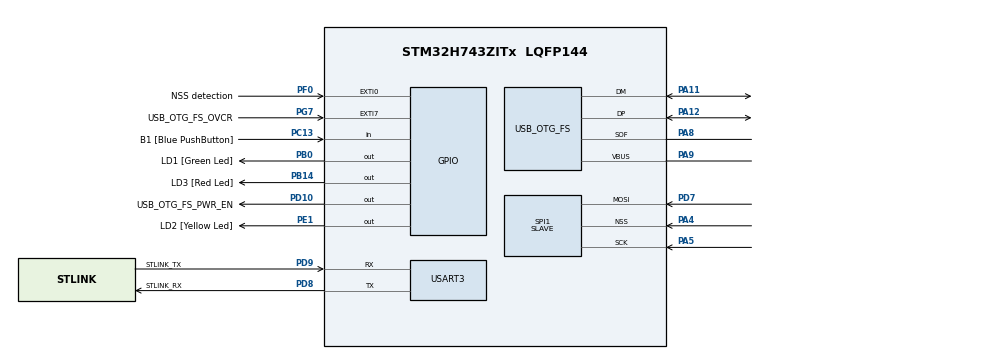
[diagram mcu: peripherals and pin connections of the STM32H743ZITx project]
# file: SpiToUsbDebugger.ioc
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Mcu.Family=STM32H7
PD7.Mode=RX_Only_Simplex_Unidirect_Slave
USB_DEVICE.CLASS_NAME_FS=CDC
RCC.CortexFreq_Value=96000000
SPI1.VirtualType=VM_SLAVE
PH0-OSC_IN\ (PH0).Signal=RCC_OSC_IN
PB14.GPIO_Label=LD3 [Red Led]
PC15-OSC32_OUT\ (OSC32_OUT).Mode=LSE-External-Oscillator
RCC.PLLFRACN=0
PA11.Mode=Device_Only
PB0.GPIO_Label=LD1 [Green Led]
USB_DEVICE.VirtualMode-CDC_FS=Cdc
NVIC.TIM1_UP_IRQn=true\:0\:0\:false\:false\:true\:true\:true
PC13.GPIO_Label=B1 [Blue PushButton]
PB13.Signal=ETH_TXD1
PG13.Signal=ETH_TXD0
PD9.Mode=Asynchronous
PG11.Signal=ETH_TX_EN
RCC.SYSCLKSource=RCC_SYSCLKSOURCE_PLLCLK
ProjectManager.StackSize=0x500
Dma.SPI1_RX.0.SyncRequestNumber=1
USART3.VirtualMode-Asynchronous=VM_ASYNC
PA12.Signal=USB_OTG_FS_DP
TIM1.Prescaler=95
Dma.SPI1_RX.0.Direction=DMA_PERIPH_TO_MEMORY
PA4.Mode=NSS_Signal_Hard_Input
SPI1.Direction=SPI_DIRECTION_2LINES_RXONLY
RCC.HCLKFreq_Value=96000000
PD8.Signal=USART3_TX
PE1.Signal=GPIO_Output
RCC.HSE_VALUE=8000000
RCC.DIVM1=1
Dma.SPI1_RX.0.RequestNumber=1
Dma.SPI1_RX.0.PeriphInc=DMA_PINC_DISABLE
Dma.SPI1_RX.0.SyncEnable=DISABLE
SPI1.DataSize=SPI_DATASIZE_8BIT
PA8.Signal=USB_OTG_FS_SOF
SPI1.VirtualNSS=VM_NSSHARD
USB_OTG_FS.dma_enable=DISABLE
Dma.SPI1_RX.0.Polarity=HAL_DMAMUX_REQ_GEN_RISING
VP_TIM1_VS_ClockSourceINT.Mode=Internal
RCC.APB3Freq_Value=96000000
Mcu.Package=LQFP144
NVIC.OTG_FS_IRQn=true\:0\:0\:false\:false\:true\:false\:true
USB_OTG_FS.VirtualMode=Device_Only
PC14-OSC32_IN\ (OSC32_IN).Mode=LSE-External-Oscillator
RCC.APB4Freq_Value=96000000
NVIC.DMA1_Stream0_IRQn=true\:0\:0\:false\:false\:true\:false\:true
PF0.Signal=GPXTI0
PC5.Signal=ETH_RXD1
TIM1.Period=333
Dma.Request0=SPI1_RX
PH0-OSC_IN\ (PH0).Mode=HSE-External-Clock-Source
PA5.Mode=RX_Only_Simplex_Unidirect_Slave
RCC.DIVQ1=4
PG7.Signal=GPXTI7
PD9.GPIO_Label=STLINK_TX
USB_DEVICE.VirtualModeFS=Cdc_FS
PC13.Signal=GPIO_Input
PC4.Signal=ETH_RXD0
PD7.Signal=SPI1_MOSI
RCC.D2PPRE1=RCC_APB1_DIV2
PD9.Signal=USART3_RX
Dma.SPI1_RX.0.Mode=DMA_CIRCULAR
PH1-OSC_OUT\ (PH1).Signal=RCC_OSC_OUT
PD8.GPIO_Label=STLINK_RX
PD10.Signal=GPIO_Output
Dma.SPI1_RX.0.FIFOMode=DMA_FIFOMODE_DISABLE
PA9.Mode=Activate_VBUS
ProjectManager.TargetToolchain=STM32CubeIDE
PC15-OSC32_OUT\ (OSC32_OUT).Signal=RCC_OSC32_OUT
VP_USB_DEVICE_VS_USB_DEVICE_CDC_FS.Mode=CDC_FS
PA9.Signal=USB_OTG_FS_VBUS
RCC.DIVN1=24
RCC.USBFreq_Value=48000000
Dma.SPI1_RX.0.EventEnable=DISABLE
PD10.GPIO_Label=USB_OTG_FS_PWR_EN
PD8.Mode=Asynchronous
PA1.Signal=ETH_REF_CLK
PB14.Signal=GPIO_Output
PA5.Signal=SPI1_SCK
board=NUCLEO-H743ZI2
PE1.GPIO_Label=LD2 [Yellow Led]
NVIC.SPI1_IRQn=true\:0\:0\:false\:false\:true\:true\:true
RCC.APB2Freq_Value=96000000
SPI1.Mode=SPI_MODE_SLAVE
PG7.GPIO_Label=USB_OTG_FS_OVCR
Dma.SPI1_RX.0.Instance=DMA1_Stream0
RCC.ADCFreq_Value=16125000
Dma.SPI1_RX.0.PeriphDataAlignment=DMA_PDATAALIGN_BYTE
Dma.SPI1_RX.0.SyncSignalID=NONE
Dma.SPI1_RX.0.MemDataAlignment=DMA_MDATAALIGN_BYTE
Mcu.Name=STM32H743ZITx
Dma.SPI1_RX.0.MemInc=DMA_MINC_ENABLE
PA2.Signal=ETH_MDIO
NVIC.EXTI0_IRQn=true\:0\:0\:false\:false\:true\:true\:true
PA4.Signal=SPI1_NSS
RCC.SYSCLKFreq_VALUE=96000000
Dma.SPI1_RX.0.SignalID=NONE
PA12.Mode=Device_Only
PC14-OSC32_IN\ (OSC32_IN).Signal=RCC_OSC32_IN
PA11.Signal=USB_OTG_FS_DM
ProjectManager.HeapSize=0x200
Dma.SPI1_RX.0.Priority=DMA_PRIORITY_LOW
Dma.SPI1_RX.0.SyncPolarity=HAL_DMAMUX_SYNC_NO_EVENT
NVIC.PriorityGroup=NVIC_PRIORITYGROUP_4
PF0.GPIO_Label=NSS detection
PA8.Mode=Activate_SOF_FS
RCC.APB1Freq_Value=48000000
PB0.Signal=GPIO_Output
PC1.Signal=ETH_MDC
PA7.Signal=ETH_CRS_DV

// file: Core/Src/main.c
/* USER CODE BEGIN Header */
/**
  ******************************************************************************
  * @file           : main.c
  * @brief          : Main program body
  ******************************************************************************
  * @attention
  *
  * <h2><center>&copy; Copyright (c) 2024 STMicroelectronics.
  * All rights reserved.</center></h2>
  *
  * This software component is licensed by ST under Ultimate Liberty license
  * SLA0044, the "License"; You may not use this file except in compliance with
  * the License. You may obtain a copy of the License at:
  *                             www.st.com/SLA0044
  *
  ******************************************************************************
  */
/* USER CODE END Header */
#include "main.h"
#include "usb_device.h"

/* USER CODE BEGIN Includes */
#include "usbd_cdc_if.h"
extern uint8_t FlushFlag;
/* USER CODE END Includes */

/* USER CODE BEGIN PM */
uint32_t gData_from_spi;
/* USER CODE END PM */

SPI_HandleTypeDef hspi1;
DMA_HandleTypeDef hdma_spi1_rx;

TIM_HandleTypeDef htim1;

UART_HandleTypeDef huart3;

/* USER CODE BEGIN PV */
int g_enable_usb_push;
/* USER CODE END PV */

void SystemClock_Config(void);
static void MX_GPIO_Init(void);
static void MX_DMA_Init(void);
static void MX_SPI1_Init(void);
static void MX_USART3_UART_Init(void);
static void MX_TIM1_Init(void);

/* USER CODE BEGIN 0 */

void HAL_GPIO_EXTI_Callback(uint16_t GPIO_Pin)
{
	HAL_SPI_Receive_DMA(&hspi1, (uint8_t*)&gData_from_spi, 4);
	HAL_NVIC_DisableIRQ(EXTI0_IRQn);

}

void HAL_SPI_RxCpltCallback(SPI_HandleTypeDef *hspi)
{
	CDC_TransmitWithFifo_FS((uint8_t*)&gData_from_spi, sizeof(gData_from_spi));
	 //HAL_SPI_Receive_IT(&hspi1, (uint8_t*)&gData_from_spi, 4);
	//static int state = 0;
	// we have new data from SPI
//	switch (state)
//	{
//	case 0:
//		gDataAssembly = 0;
//		if(gData_from_spi == 0)
//			state =1;
//		break;
//	case 1:
//		gDataAssembly |= (uint32_t)gData_from_spi;
//		state = 2;
//		break;
//	case 2:
//		gDataAssembly |= (uint32_t)gData_from_spi<<8;
//		state = 3;
//		break;
//	case 3:
//		gDataAssembly |= (uint32_t)gData_from_spi<<16;
//		state = 4;
//		break;
//	case 4:
//		gDataAssembly |= (uint32_t)gData_from_spi<<24;
//		state = 5;
//		break;
//	case 5:
//		if(gData_from_spi == 0xff)
//			CDC_TransmitWithFifo_FS((uint8_t*)&gDataAssembly, sizeof(gDataAssembly));
//		state = 0;
//		break;
//	}

}
/* USER CODE END 0 */

int main(void)
{

  /* MCU Configuration--------------------------------------------------------*/

  /* Reset of all peripherals, Initializes the Flash interface and the Systick. */
  HAL_Init();

  /* Configure the system clock */
  SystemClock_Config();

  /* Initialize all configured peripherals */
  MX_GPIO_Init();
  MX_DMA_Init();
  MX_SPI1_Init();
  MX_USART3_UART_Init();
  MX_USB_DEVICE_Init();
  MX_TIM1_Init();
  /* USER CODE BEGIN 2 */
  //HAL_TIM_Base_Start_IT(&htim1);
  HAL_NVIC_SetPriority(EXTI0_IRQn, 10, 10);
  HAL_NVIC_EnableIRQ(EXTI0_IRQn);

 // CLEAR_BIT(hspi1.Instance->CR1 , SPI_CR1_SPE);
  /* USER CODE END 2 */

  /* Infinite loop */
  while (1)
  {
	  if(FlushFlag)
	  {
		  uint8_t retval = CDC_TxFifoFlush();
		  if(retval == 0)
		  {
			  FlushFlag = 0;
		  }
	  }
  }
}

void SystemClock_Config(void)
{
  RCC_OscInitTypeDef RCC_OscInitStruct = {0};
  RCC_ClkInitTypeDef RCC_ClkInitStruct = {0};

  /** Supply configuration update enable
  */
  HAL_PWREx_ConfigSupply(PWR_LDO_SUPPLY);
  /** Configure the main internal regulator output voltage
  */
  __HAL_PWR_VOLTAGESCALING_CONFIG(PWR_REGULATOR_VOLTAGE_SCALE3);

  while(!__HAL_PWR_GET_FLAG(PWR_FLAG_VOSRDY)) {}
  /** Initializes the RCC Oscillators according to the specified parameters
  * in the RCC_OscInitTypeDef structure.
  */
  RCC_OscInitStruct.OscillatorType = RCC_OSCILLATORTYPE_HSE;
  RCC_OscInitStruct.HSEState = RCC_HSE_BYPASS;
  RCC_OscInitStruct.PLL.PLLState = RCC_PLL_ON;
  RCC_OscInitStruct.PLL.PLLSource = RCC_PLLSOURCE_HSE;
  RCC_OscInitStruct.PLL.PLLM = 1;
  RCC_OscInitStruct.PLL.PLLN = 24;
  RCC_OscInitStruct.PLL.PLLP = 2;
  RCC_OscInitStruct.PLL.PLLQ = 4;
  RCC_OscInitStruct.PLL.PLLR = 2;
  RCC_OscInitStruct.PLL.PLLRGE = RCC_PLL1VCIRANGE_3;
  RCC_OscInitStruct.PLL.PLLVCOSEL = RCC_PLL1VCOWIDE;
  RCC_OscInitStruct.PLL.PLLFRACN = 0;
  if (HAL_RCC_OscConfig(&RCC_OscInitStruct) != HAL_OK)
  {
    Error_Handler();
  }
  /** Initializes the CPU, AHB and APB buses clocks
  */
  RCC_ClkInitStruct.ClockType = RCC_CLOCKTYPE_HCLK|RCC_CLOCKTYPE_SYSCLK
                              |RCC_CLOCKTYPE_PCLK1|RCC_CLOCKTYPE_PCLK2
                              |RCC_CLOCKTYPE_D3PCLK1|RCC_CLOCKTYPE_D1PCLK1;
  RCC_ClkInitStruct.SYSCLKSource = RCC_SYSCLKSOURCE_PLLCLK;
  RCC_ClkInitStruct.SYSCLKDivider = RCC_SYSCLK_DIV1;
  RCC_ClkInitStruct.AHBCLKDivider = RCC_HCLK_DIV1;
  RCC_ClkInitStruct.APB3CLKDivider = RCC_APB3_DIV1;
  RCC_ClkInitStruct.APB1CLKDivider = RCC_APB1_DIV2;
  RCC_ClkInitStruct.APB2CLKDivider = RCC_APB2_DIV1;
  RCC_ClkInitStruct.APB4CLKDivider = RCC_APB4_DIV1;

  if (HAL_RCC_ClockConfig(&RCC_ClkInitStruct, FLASH_LATENCY_2) != HAL_OK)
  {
    Error_Handler();
  }
}

static void MX_SPI1_Init(void)
{

  /* SPI1 parameter configuration*/
  hspi1.Instance = SPI1;
  hspi1.Init.Mode = SPI_MODE_SLAVE;
  hspi1.Init.Direction = SPI_DIRECTION_2LINES_RXONLY;
  hspi1.Init.DataSize = SPI_DATASIZE_8BIT;
  hspi1.Init.CLKPolarity = SPI_POLARITY_LOW;
  hspi1.Init.CLKPhase = SPI_PHASE_1EDGE;
  hspi1.Init.NSS = SPI_NSS_HARD_INPUT;
  hspi1.Init.FirstBit = SPI_FIRSTBIT_MSB;
  hspi1.Init.TIMode = SPI_TIMODE_DISABLE;
  hspi1.Init.CRCCalculation = SPI_CRCCALCULATION_DISABLE;
  hspi1.Init.CRCPolynomial = 0x0;
  hspi1.Init.NSSPMode = SPI_NSS_PULSE_DISABLE;
  hspi1.Init.NSSPolarity = SPI_NSS_POLARITY_LOW;
  hspi1.Init.FifoThreshold = SPI_FIFO_THRESHOLD_01DATA;
  hspi1.Init.TxCRCInitializationPattern = SPI_CRC_INITIALIZATION_ALL_ZERO_PATTERN;
  hspi1.Init.RxCRCInitializationPattern = SPI_CRC_INITIALIZATION_ALL_ZERO_PATTERN;
  hspi1.Init.MasterSSIdleness = SPI_MASTER_SS_IDLENESS_00CYCLE;
  hspi1.Init.MasterInterDataIdleness = SPI_MASTER_INTERDATA_IDLENESS_00CYCLE;
  hspi1.Init.MasterReceiverAutoSusp = SPI_MASTER_RX_AUTOSUSP_DISABLE;
  hspi1.Init.MasterKeepIOState = SPI_MASTER_KEEP_IO_STATE_DISABLE;
  hspi1.Init.IOSwap = SPI_IO_SWAP_DISABLE;
  if (HAL_SPI_Init(&hspi1) != HAL_OK)
  {
    Error_Handler();
  }

}

static void MX_TIM1_Init(void)
{

  TIM_ClockConfigTypeDef sClockSourceConfig = {0};
  TIM_MasterConfigTypeDef sMasterConfig = {0};

  htim1.Instance = TIM1;
  htim1.Init.Prescaler = 95;
  htim1.Init.CounterMode = TIM_COUNTERMODE_UP;
  htim1.Init.Period = 333;
  htim1.Init.ClockDivision = TIM_CLOCKDIVISION_DIV1;
  htim1.Init.RepetitionCounter = 0;
  htim1.Init.AutoReloadPreload = TIM_AUTORELOAD_PRELOAD_DISABLE;
  if (HAL_TIM_Base_Init(&htim1) != HAL_OK)
  {
    Error_Handler();
  }
  sClockSourceConfig.ClockSource = TIM_CLOCKSOURCE_INTERNAL;
  if (HAL_TIM_ConfigClockSource(&htim1, &sClockSourceConfig) != HAL_OK)
  {
    Error_Handler();
  }
  sMasterConfig.MasterOutputTrigger = TIM_TRGO_RESET;
  sMasterConfig.MasterOutputTrigger2 = TIM_TRGO2_RESET;
  sMasterConfig.MasterSlaveMode = TIM_MASTERSLAVEMODE_DISABLE;
  if (HAL_TIMEx_MasterConfigSynchronization(&htim1, &sMasterConfig) != HAL_OK)
  {
    Error_Handler();
  }

}

static void MX_USART3_UART_Init(void)
{

  huart3.Instance = USART3;
  huart3.Init.BaudRate = 115200;
  huart3.Init.WordLength = UART_WORDLENGTH_8B;
  huart3.Init.StopBits = UART_STOPBITS_1;
  huart3.Init.Parity = UART_PARITY_NONE;
  huart3.Init.Mode = UART_MODE_TX_RX;
  huart3.Init.HwFlowCtl = UART_HWCONTROL_NONE;
  huart3.Init.OverSampling = UART_OVERSAMPLING_16;
  huart3.Init.OneBitSampling = UART_ONE_BIT_SAMPLE_DISABLE;
  huart3.Init.ClockPrescaler = UART_PRESCALER_DIV1;
  huart3.AdvancedInit.AdvFeatureInit = UART_ADVFEATURE_NO_INIT;
  if (HAL_UART_Init(&huart3) != HAL_OK)
  {
    Error_Handler();
  }
  if (HAL_UARTEx_SetTxFifoThreshold(&huart3, UART_TXFIFO_THRESHOLD_1_8) != HAL_OK)
  {
    Error_Handler();
  }
  if (HAL_UARTEx_SetRxFifoThreshold(&huart3, UART_RXFIFO_THRESHOLD_1_8) != HAL_OK)
  {
    Error_Handler();
  }
  if (HAL_UARTEx_DisableFifoMode(&huart3) != HAL_OK)
  {
    Error_Handler();
  }

}

static void MX_DMA_Init(void)
{

  /* DMA controller clock enable */
  __HAL_RCC_DMA1_CLK_ENABLE();

  /* DMA interrupt init */
  /* DMA1_Stream0_IRQn interrupt configuration */
  HAL_NVIC_SetPriority(DMA1_Stream0_IRQn, 0, 0);
  HAL_NVIC_EnableIRQ(DMA1_Stream0_IRQn);

}

static void MX_GPIO_Init(void)
{
  GPIO_InitTypeDef GPIO_InitStruct = {0};

  /* GPIO Ports Clock Enable */
  __HAL_RCC_GPIOC_CLK_ENABLE();
  __HAL_RCC_GPIOF_CLK_ENABLE();
  __HAL_RCC_GPIOH_CLK_ENABLE();
  __HAL_RCC_GPIOA_CLK_ENABLE();
  __HAL_RCC_GPIOB_CLK_ENABLE();
  __HAL_RCC_GPIOD_CLK_ENABLE();
  __HAL_RCC_GPIOG_CLK_ENABLE();
  __HAL_RCC_GPIOE_CLK_ENABLE();

  /*Configure GPIO pin Output Level */
  HAL_GPIO_WritePin(GPIOB, LD1_Pin|LD3_Pin, GPIO_PIN_RESET);

  /*Configure GPIO pin Output Level */
  HAL_GPIO_WritePin(USB_OTG_FS_PWR_EN_GPIO_Port, USB_OTG_FS_PWR_EN_Pin, GPIO_PIN_RESET);

  /*Configure GPIO pin Output Level */
  HAL_GPIO_WritePin(LD2_GPIO_Port, LD2_Pin, GPIO_PIN_RESET);

  /*Configure GPIO pin : B1_Pin */
  GPIO_InitStruct.Pin = B1_Pin;
  GPIO_InitStruct.Mode = GPIO_MODE_INPUT;
  GPIO_InitStruct.Pull = GPIO_NOPULL;
  HAL_GPIO_Init(B1_GPIO_Port, &GPIO_InitStruct);

  /*Configure GPIO pin : NSS_detection_Pin */
  GPIO_InitStruct.Pin = NSS_detection_Pin;
  GPIO_InitStruct.Mode = GPIO_MODE_IT_RISING;
  GPIO_InitStruct.Pull = GPIO_NOPULL;
  HAL_GPIO_Init(NSS_detection_GPIO_Port, &GPIO_InitStruct);

  /*Configure GPIO pins : PC1 PC4 PC5 */
  GPIO_InitStruct.Pin = GPIO_PIN_1|GPIO_PIN_4|GPIO_PIN_5;
  GPIO_InitStruct.Mode = GPIO_MODE_AF_PP;
  GPIO_InitStruct.Pull = GPIO_NOPULL;
  GPIO_InitStruct.Speed = GPIO_SPEED_FREQ_LOW;
  GPIO_InitStruct.Alternate = GPIO_AF11_ETH;
  HAL_GPIO_Init(GPIOC, &GPIO_InitStruct);

  /*Configure GPIO pins : PA1 PA2 PA7 */
  GPIO_InitStruct.Pin = GPIO_PIN_1|GPIO_PIN_2|GPIO_PIN_7;
  GPIO_InitStruct.Mode = GPIO_MODE_AF_PP;
  GPIO_InitStruct.Pull = GPIO_NOPULL;
  GPIO_InitStruct.Speed = GPIO_SPEED_FREQ_LOW;
  GPIO_InitStruct.Alternate = GPIO_AF11_ETH;
  HAL_GPIO_Init(GPIOA, &GPIO_InitStruct);

  /*Configure GPIO pins : LD1_Pin LD3_Pin */
  GPIO_InitStruct.Pin = LD1_Pin|LD3_Pin;
  GPIO_InitStruct.Mode = GPIO_MODE_OUTPUT_PP;
  GPIO_InitStruct.Pull = GPIO_NOPULL;
  GPIO_InitStruct.Speed = GPIO_SPEED_FREQ_LOW;
  HAL_GPIO_Init(GPIOB, &GPIO_InitStruct);

  /*Configure GPIO pin : PB13 */
  GPIO_InitStruct.Pin = GPIO_PIN_13;
  GPIO_InitStruct.Mode = GPIO_MODE_AF_PP;
  GPIO_InitStruct.Pull = GPIO_NOPULL;
  GPIO_InitStruct.Speed = GPIO_SPEED_FREQ_LOW;
  GPIO_InitStruct.Alternate = GPIO_AF11_ETH;
  HAL_GPIO_Init(GPIOB, &GPIO_InitStruct);

  /*Configure GPIO pin : USB_OTG_FS_PWR_EN_Pin */
  GPIO_InitStruct.Pin = USB_OTG_FS_PWR_EN_Pin;
  GPIO_InitStruct.Mode = GPIO_MODE_OUTPUT_PP;
  GPIO_InitStruct.Pull = GPIO_NOPULL;
  GPIO_InitStruct.Speed = GPIO_SPEED_FREQ_LOW;
  HAL_GPIO_Init(USB_OTG_FS_PWR_EN_GPIO_Port, &GPIO_InitStruct);

  /*Configure GPIO pin : USB_OTG_FS_OVCR_Pin */
  GPIO_InitStruct.Pin = USB_OTG_FS_OVCR_Pin;
  GPIO_InitStruct.Mode = GPIO_MODE_IT_RISING;
  GPIO_InitStruct.Pull = GPIO_NOPULL;
  HAL_GPIO_Init(USB_OTG_FS_OVCR_GPIO_Port, &GPIO_InitStruct);

  /*Configure GPIO pins : PG11 PG13 */
  GPIO_InitStruct.Pin = GPIO_PIN_11|GPIO_PIN_13;
  GPIO_InitStruct.Mode = GPIO_MODE_AF_PP;
  GPIO_InitStruct.Pull = GPIO_NOPULL;
  GPIO_InitStruct.Speed = GPIO_SPEED_FREQ_LOW;
  GPIO_InitStruct.Alternate = GPIO_AF11_ETH;
  HAL_GPIO_Init(GPIOG, &GPIO_InitStruct);

  /*Configure GPIO pin : LD2_Pin */
  GPIO_InitStruct.Pin = LD2_Pin;
  GPIO_InitStruct.Mode = GPIO_MODE_OUTPUT_PP;
  GPIO_InitStruct.Pull = GPIO_NOPULL;
  GPIO_InitStruct.Speed = GPIO_SPEED_FREQ_LOW;
  HAL_GPIO_Init(LD2_GPIO_Port, &GPIO_InitStruct);

  /* EXTI interrupt init*/
  HAL_NVIC_SetPriority(EXTI0_IRQn, 0, 0);
  HAL_NVIC_EnableIRQ(EXTI0_IRQn);

}

void Error_Handler(void)
{
  __disable_irq();
  while (1)
  {
  }
}

/************************ (C) COPYRIGHT STMicroelectronics *****END OF FILE****/
